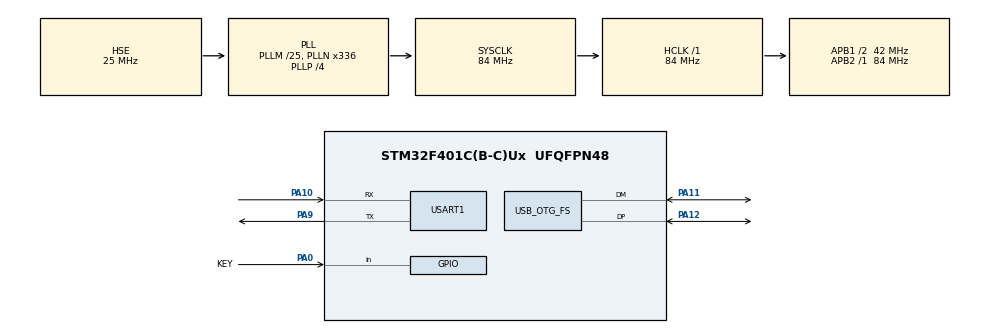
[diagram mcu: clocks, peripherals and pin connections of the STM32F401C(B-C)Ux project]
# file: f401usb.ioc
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Mcu.Family=STM32F4
Mcu.Name=STM32F401C(B-C)Ux
Mcu.Package=UFQFPN48
NVIC.OTG_FS_IRQn=true\:0\:0\:false\:false\:true\:false\:true\:true
NVIC.PriorityGroup=NVIC_PRIORITYGROUP_4
PA0-WKUP.GPIO_Label=KEY
PA0-WKUP.GPIO_PuPd=GPIO_PULLUP
PA0-WKUP.Signal=GPIO_Input
PA10.Mode=Asynchronous
PA10.Signal=USART1_RX
PA11.Mode=Device_Only
PA11.Signal=USB_OTG_FS_DM
PA12.Mode=Device_Only
PA12.Signal=USB_OTG_FS_DP
PA9.Mode=Asynchronous
PA9.Signal=USART1_TX
PC14-OSC32_IN.Mode=LSE-External-Oscillator
PC14-OSC32_IN.Signal=RCC_OSC32_IN
PC15-OSC32_OUT.Mode=LSE-External-Oscillator
PC15-OSC32_OUT.Signal=RCC_OSC32_OUT
PH0\ -\ OSC_IN.Mode=HSE-External-Oscillator
PH0\ -\ OSC_IN.Signal=RCC_OSC_IN
PH1\ -\ OSC_OUT.Mode=HSE-External-Oscillator
PH1\ -\ OSC_OUT.Signal=RCC_OSC_OUT
ProjectManager.HeapSize=0x200
ProjectManager.StackSize=0x400
ProjectManager.TargetToolchain=Makefile
RCC.48MHZClocksFreq_Value=48000000
RCC.AHBFreq_Value=84000000
RCC.APB1CLKDivider=RCC_HCLK_DIV2
RCC.APB1Freq_Value=42000000
RCC.APB1TimFreq_Value=84000000
RCC.APB2Freq_Value=84000000
RCC.APB2TimFreq_Value=84000000
RCC.CortexFreq_Value=84000000
RCC.HCLKFreq_Value=84000000
RCC.HSE_VALUE=25000000
RCC.HSI_VALUE=16000000
RCC.PLLM=25
RCC.PLLN=336
RCC.PLLP=RCC_PLLP_DIV4
RCC.PLLQ=7
RCC.SYSCLKFreq_VALUE=84000000
RCC.SYSCLKSource=RCC_SYSCLKSOURCE_PLLCLK
RCC.VCOOutputFreq_Value=336000000
USART1.VirtualMode=VM_ASYNC
USB_DEVICE.CLASS_NAME_FS=DFU
USB_DEVICE.USBD_DFU_APP_DEFAULT_ADD=0x08010000
USB_DEVICE.USBD_DFU_MEDIA=@Internal Flash   /0x08010000/01*064Kg
USB_DEVICE.VirtualMode=Dfu
USB_DEVICE.VirtualModeFS=Dfu_FS
USB_OTG_FS.VirtualMode=Device_Only
VP_USB_DEVICE_VS_USB_DEVICE_DFU_FS.Mode=DFU_FS
board=custom

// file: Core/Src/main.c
/* USER CODE BEGIN Header */
/**
  ******************************************************************************
  * @file           : main.c
  * @brief          : Main program body
  ******************************************************************************
  * @attention
  *
  * Copyright (c) 2022 STMicroelectronics.
  * All rights reserved.
  *
  * This software is licensed under terms that can be found in the LICENSE file
  * in the root directory of this software component.
  * If no LICENSE file comes with this software, it is provided AS-IS.
  *
  ******************************************************************************
  */
/* USER CODE END Header */
#include "main.h"
#include "usb_device.h"

 UART_HandleTypeDef huart1;

void SystemClock_Config(void);
static void MX_GPIO_Init(void);
static void MX_USART1_UART_Init(void);

int main(void)
{

  /* MCU Configuration--------------------------------------------------------*/

  /* Reset of all peripherals, Initializes the Flash interface and the Systick. */
  HAL_Init();

  /* Configure the system clock */
  SystemClock_Config();

  /* USER CODE BEGIN SysInit */
  typedef  void (*pFunction)(void);

  pFunction JumpToApplication;
  uint32_t JumpAddress;

  MX_GPIO_Init();

  if(HAL_GPIO_ReadPin(KEY_GPIO_Port, KEY_Pin) == GPIO_PIN_SET)
  {
    /* Test if user code is programmed starting from address 0x08010000 */
    if (((*(__IO uint32_t *) USBD_DFU_APP_DEFAULT_ADD) & 0x2FFC0000) == 0x20000000)
    {
      __disable_irq();
      JumpAddress = *(__IO uint32_t *) (USBD_DFU_APP_DEFAULT_ADD + 4);
      JumpToApplication = (pFunction) JumpAddress;
      JumpToApplication();
    }
  }

  /* USER CODE END SysInit */

  /* Initialize all configured peripherals */
  MX_GPIO_Init();
  MX_USB_DEVICE_Init();
  MX_USART1_UART_Init();

  /* Infinite loop */
  while (1)
  {

  }
}

void SystemClock_Config(void)
{
  RCC_OscInitTypeDef RCC_OscInitStruct = {0};
  RCC_ClkInitTypeDef RCC_ClkInitStruct = {0};

  /** Configure the main internal regulator output voltage
  */
  __HAL_RCC_PWR_CLK_ENABLE();
  __HAL_PWR_VOLTAGESCALING_CONFIG(PWR_REGULATOR_VOLTAGE_SCALE2);

  /** Initializes the RCC Oscillators according to the specified parameters
  * in the RCC_OscInitTypeDef structure.
  */
  RCC_OscInitStruct.OscillatorType = RCC_OSCILLATORTYPE_HSE;
  RCC_OscInitStruct.HSEState = RCC_HSE_ON;
  RCC_OscInitStruct.PLL.PLLState = RCC_PLL_ON;
  RCC_OscInitStruct.PLL.PLLSource = RCC_PLLSOURCE_HSE;
  RCC_OscInitStruct.PLL.PLLM = 25;
  RCC_OscInitStruct.PLL.PLLN = 336;
  RCC_OscInitStruct.PLL.PLLP = RCC_PLLP_DIV4;
  RCC_OscInitStruct.PLL.PLLQ = 7;
  if (HAL_RCC_OscConfig(&RCC_OscInitStruct) != HAL_OK)
  {
    Error_Handler();
  }

  /** Initializes the CPU, AHB and APB buses clocks
  */
  RCC_ClkInitStruct.ClockType = RCC_CLOCKTYPE_HCLK|RCC_CLOCKTYPE_SYSCLK
                              |RCC_CLOCKTYPE_PCLK1|RCC_CLOCKTYPE_PCLK2;
  RCC_ClkInitStruct.SYSCLKSource = RCC_SYSCLKSOURCE_PLLCLK;
  RCC_ClkInitStruct.AHBCLKDivider = RCC_SYSCLK_DIV1;
  RCC_ClkInitStruct.APB1CLKDivider = RCC_HCLK_DIV2;
  RCC_ClkInitStruct.APB2CLKDivider = RCC_HCLK_DIV1;

  if (HAL_RCC_ClockConfig(&RCC_ClkInitStruct, FLASH_LATENCY_2) != HAL_OK)
  {
    Error_Handler();
  }
}

static void MX_USART1_UART_Init(void)
{

  huart1.Instance = USART1;
  huart1.Init.BaudRate = 115200;
  huart1.Init.WordLength = UART_WORDLENGTH_8B;
  huart1.Init.StopBits = UART_STOPBITS_1;
  huart1.Init.Parity = UART_PARITY_NONE;
  huart1.Init.Mode = UART_MODE_TX_RX;
  huart1.Init.HwFlowCtl = UART_HWCONTROL_NONE;
  huart1.Init.OverSampling = UART_OVERSAMPLING_16;
  if (HAL_UART_Init(&huart1) != HAL_OK)
  {
    Error_Handler();
  }

}

static void MX_GPIO_Init(void)
{
  GPIO_InitTypeDef GPIO_InitStruct = {0};

  /* GPIO Ports Clock Enable */
  __HAL_RCC_GPIOC_CLK_ENABLE();
  __HAL_RCC_GPIOH_CLK_ENABLE();
  __HAL_RCC_GPIOA_CLK_ENABLE();

  /*Configure GPIO pin : KEY_Pin */
  GPIO_InitStruct.Pin = KEY_Pin;
  GPIO_InitStruct.Mode = GPIO_MODE_INPUT;
  GPIO_InitStruct.Pull = GPIO_PULLUP;
  HAL_GPIO_Init(KEY_GPIO_Port, &GPIO_InitStruct);

}

void Error_Handler(void)
{
  __disable_irq();
  while (1)
  {
  }
}
